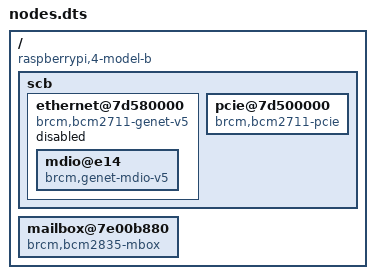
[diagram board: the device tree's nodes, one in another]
/dts-v1/;
/ {
	compatible = "raspberrypi,4-model-b", "brcm,bcm2711";
	#address-cells = <2>;
	#size-cells = <1>;
	scb {
		ethernet@7d580000 {
			compatible = "brcm,bcm2711-genet-v5";
			status = "disabled";
			mdio@e14 {
				compatible = "brcm,genet-mdio-v5";
				status = "okay";
			};
		};
		pcie@7d500000 {
			compatible = "brcm,bcm2711-pcie";
			status = "okay";
		};
	};
	mailbox@7e00b880 {
		compatible = "brcm,bcm2835-mbox";
	};
};
